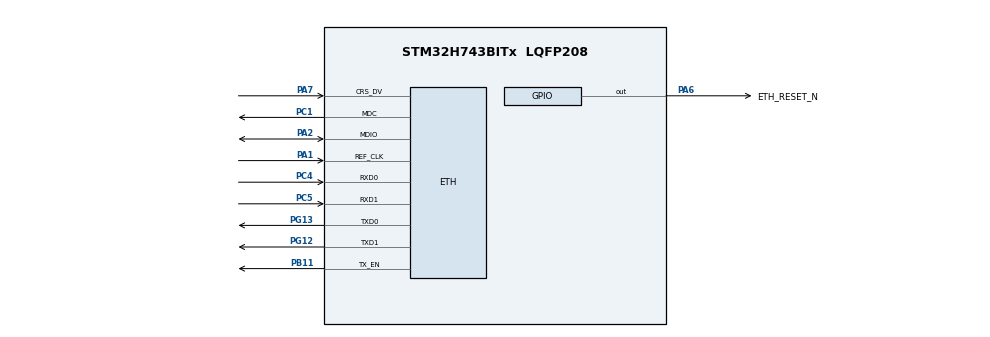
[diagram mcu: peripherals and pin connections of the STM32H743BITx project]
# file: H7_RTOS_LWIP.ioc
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CORTEX_M7.AccessPermission_S-Cortex_Memory_Protection_Unit_Region1_Settings_S=MPU_REGION_FULL_ACCESS
CORTEX_M7.AccessPermission_S-Cortex_Memory_Protection_Unit_Region2_Settings_S=MPU_REGION_FULL_ACCESS
CORTEX_M7.BaseAddress_S-Cortex_Memory_Protection_Unit_Region1_Settings_S=0x30020000
CORTEX_M7.BaseAddress_S-Cortex_Memory_Protection_Unit_Region2_Settings_S=0x30040000
CORTEX_M7.CPU_DCache=Enabled
CORTEX_M7.CPU_ICache=Enabled
CORTEX_M7.DisableExec_S-Cortex_Memory_Protection_Unit_Region1_Settings_S=MPU_INSTRUCTION_ACCESS_DISABLE
CORTEX_M7.DisableExec_S-Cortex_Memory_Protection_Unit_Region2_Settings_S=MPU_INSTRUCTION_ACCESS_DISABLE
CORTEX_M7.Enable_S-Cortex_Memory_Protection_Unit_Region1_Settings_S=MPU_REGION_ENABLE
CORTEX_M7.Enable_S-Cortex_Memory_Protection_Unit_Region2_Settings_S=MPU_REGION_ENABLE
CORTEX_M7.IsBufferable_S-Cortex_Memory_Protection_Unit_Region2_Settings_S=MPU_ACCESS_BUFFERABLE
CORTEX_M7.IsCacheable_S-Cortex_Memory_Protection_Unit_Region2_Settings_S=MPU_ACCESS_NOT_CACHEABLE
CORTEX_M7.IsShareable_S-Cortex_Memory_Protection_Unit_Region2_Settings_S=MPU_ACCESS_SHAREABLE
CORTEX_M7.Size_S-Cortex_Memory_Protection_Unit_Region1_Settings_S=MPU_REGION_SIZE_128KB
CORTEX_M7.Size_S-Cortex_Memory_Protection_Unit_Region2_Settings_S=MPU_REGION_SIZE_512B
CORTEX_M7.TypeExtField_S-Cortex_Memory_Protection_Unit_Region1_Settings_S=MPU_TEX_LEVEL1
CORTEX_M7.TypeExtField_S-Cortex_Memory_Protection_Unit_Region2_Settings_S=MPU_TEX_LEVEL0
CORTEX_M7.default_mode_Activation=1
ETH.MediaInterface=HAL_ETH_RMII_MODE
ETH.RxBufferAddress=0x30040200
ETH.RxDescAddress=0x30040000
ETH.TxDescAddress=0x30040080
FREERTOS.Tasks01=defaultTask,24,256,StartDefaultTask,Default,NULL,Dynamic,NULL,NULL
FREERTOS.configENABLE_FPU=1
LWIP.BSP.number=1
LWIP.LWIP_RAM_HEAP_POINTER=0x30020000
LWIP.MEM_SIZE=131048
LWIP.Version=v2.1.2_Cube
LWIP0.BSP.STBoard=false
LWIP0.BSP.api=BSP_COMPONENT_DRIVER
LWIP0.BSP.component=LAN8742
LWIP0.BSP.instance=LAN8742
LWIP0.BSP.name=Driver_PHY
LWIP0.BSP.semaphore=S_LAN8742
LWIP0.BSP.solution=LAN8742
Mcu.Family=STM32H7
Mcu.Name=STM32H743BITx
Mcu.Package=LQFP208
NVIC.ETH_IRQn=true\:5\:0\:false\:false\:true\:true\:true\:true\:true
NVIC.PriorityGroup=NVIC_PRIORITYGROUP_4
NVIC.TIM6_DAC_IRQn=true\:15\:0\:false\:false\:true\:false\:false\:true\:true
NVIC.TimeBase=TIM6_DAC_IRQn
NVIC.TimeBaseIP=TIM6
PA1.GPIO_Mode=GPIO_MODE_AF_PP
PA1.GPIO_PuPd=GPIO_NOPULL
PA1.GPIO_Speed=GPIO_SPEED_FREQ_VERY_HIGH
PA1.Mode=RMII
PA1.Signal=ETH_REF_CLK
PA13\ (JTMS/SWDIO).Mode=Serial_Wire
PA13\ (JTMS/SWDIO).Signal=DEBUG_JTMS-SWDIO
PA14\ (JTCK/SWCLK).Mode=Serial_Wire
PA14\ (JTCK/SWCLK).Signal=DEBUG_JTCK-SWCLK
PA2.GPIO_Mode=GPIO_MODE_AF_PP
PA2.GPIO_PuPd=GPIO_NOPULL
PA2.GPIO_Speed=GPIO_SPEED_FREQ_VERY_HIGH
PA2.Mode=RMII
PA2.Signal=ETH_MDIO
PA6.GPIO_Label=ETH_RESET_N
PA6.GPIO_Speed=GPIO_SPEED_FREQ_VERY_HIGH
PA6.PinState=GPIO_PIN_SET
PA6.Signal=GPIO_Output
PA7.GPIO_Mode=GPIO_MODE_AF_PP
PA7.GPIO_PuPd=GPIO_NOPULL
PA7.GPIO_Speed=GPIO_SPEED_FREQ_VERY_HIGH
PA7.Mode=RMII
PA7.Signal=ETH_CRS_DV
PB11.GPIO_Mode=GPIO_MODE_AF_PP
PB11.GPIO_PuPd=GPIO_NOPULL
PB11.GPIO_Speed=GPIO_SPEED_FREQ_VERY_HIGH
PB11.Mode=RMII
PB11.Signal=ETH_TX_EN
PC1.GPIO_Mode=GPIO_MODE_AF_PP
PC1.GPIO_PuPd=GPIO_NOPULL
PC1.GPIO_Speed=GPIO_SPEED_FREQ_VERY_HIGH
PC1.Mode=RMII
PC1.Signal=ETH_MDC
PC4.GPIO_Mode=GPIO_MODE_AF_PP
PC4.GPIO_PuPd=GPIO_NOPULL
PC4.GPIO_Speed=GPIO_SPEED_FREQ_VERY_HIGH
PC4.Mode=RMII
PC4.Signal=ETH_RXD0
PC5.GPIO_Mode=GPIO_MODE_AF_PP
PC5.GPIO_PuPd=GPIO_NOPULL
PC5.GPIO_Speed=GPIO_SPEED_FREQ_VERY_HIGH
PC5.Mode=RMII
PC5.Signal=ETH_RXD1
PG12.GPIO_Mode=GPIO_MODE_AF_PP
PG12.GPIO_PuPd=GPIO_NOPULL
PG12.GPIO_Speed=GPIO_SPEED_FREQ_VERY_HIGH
PG12.Mode=RMII
PG12.Signal=ETH_TXD1
PG13.GPIO_Mode=GPIO_MODE_AF_PP
PG13.GPIO_PuPd=GPIO_NOPULL
PG13.GPIO_Speed=GPIO_SPEED_FREQ_VERY_HIGH
PG13.Mode=RMII
PG13.Signal=ETH_TXD0
PH0-OSC_IN\ (PH0).Mode=HSE-External-Oscillator
PH0-OSC_IN\ (PH0).Signal=RCC_OSC_IN
PH1-OSC_OUT\ (PH1).Mode=HSE-External-Oscillator
PH1-OSC_OUT\ (PH1).Signal=RCC_OSC_OUT
ProjectManager.HeapSize=0x800
ProjectManager.StackSize=0x800
ProjectManager.TargetToolchain=MDK-ARM V5.32
RCC.ADCFreq_Value=50390625
RCC.APB1Freq_Value=120000000
RCC.APB2Freq_Value=120000000
RCC.APB3Freq_Value=120000000
RCC.APB4Freq_Value=120000000
RCC.CortexFreq_Value=480000000
RCC.D1PPRE=RCC_APB3_DIV2
RCC.D2PPRE1=RCC_APB1_DIV2
RCC.D2PPRE2=RCC_APB2_DIV2
RCC.D3PPRE=RCC_APB4_DIV2
RCC.DIVM1=5
RCC.DIVN1=192
RCC.HCLKFreq_Value=240000000
RCC.HPRE=RCC_HCLK_DIV2
RCC.PLLSourceVirtual=RCC_PLLSOURCE_HSE
RCC.SYSCLKFreq_VALUE=480000000
RCC.SYSCLKSource=RCC_SYSCLKSOURCE_PLLCLK
RCC.USBFreq_Value=480000000
VP_FREERTOS_VS_CMSIS_V2.Mode=CMSIS_V2
VP_LWIP_VS_Enabled.Mode=Enabled
VP_MEMORYMAP_VS_MEMORYMAP.Mode=CurAppReg
VP_SYS_VS_tim6.Mode=TIM6
board=custom

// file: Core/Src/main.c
/* USER CODE BEGIN Header */
/**
  ******************************************************************************
  * @file           : main.c
  * @brief          : Main program body
  ******************************************************************************
  * @attention
  *
  * Copyright (c) 2024 STMicroelectronics.
  * All rights reserved.
  *
  * This software is licensed under terms that can be found in the LICENSE file
  * in the root directory of this software component.
  * If no LICENSE file comes with this software, it is provided AS-IS.
  *
  ******************************************************************************
  */
/* USER CODE END Header */
#include "main.h"
#include "cmsis_os.h"
#include "lwip.h"
#include "memorymap.h"
#include "gpio.h"

/* USER CODE BEGIN Includes */
#include "dwt.h"
#include "EventRecorder.h"
/* USER CODE END Includes */

void SystemClock_Config(void);
static void MPU_Config(void);
void MX_FREERTOS_Init(void);

int main(void)
{

  /* MPU Configuration--------------------------------------------------------*/
  MPU_Config();

  /* Enable the CPU Cache */

  /* Enable I-Cache---------------------------------------------------------*/
  SCB_EnableICache();

  /* Enable D-Cache---------------------------------------------------------*/
  SCB_EnableDCache();

  /* MCU Configuration--------------------------------------------------------*/

  /* Reset of all peripherals, Initializes the Flash interface and the Systick. */
  HAL_Init();

  /* Configure the system clock */
  SystemClock_Config();

  /* USER CODE BEGIN SysInit */
  __HAL_RCC_D2SRAM2_CLK_ENABLE();//Can be used even if not enabled
  __HAL_RCC_D2SRAM3_CLK_ENABLE();
  /* USER CODE END SysInit */

  /* Initialize all configured peripherals */
  MX_GPIO_Init();
  /* USER CODE BEGIN 2 */
  DWT_Init(480000000);
  EventRecorderInitialize(EventRecordAll, 1);
  /* USER CODE END 2 */

  /* Init scheduler */
  osKernelInitialize();

  /* Call init function for freertos objects (in cmsis_os2.c) */
  MX_FREERTOS_Init();

  /* Start scheduler */
  osKernelStart();

  /* We should never get here as control is now taken by the scheduler */

  /* Infinite loop */
  while (1)
  {

  }
}

void SystemClock_Config(void)
{
  RCC_OscInitTypeDef RCC_OscInitStruct = {0};
  RCC_ClkInitTypeDef RCC_ClkInitStruct = {0};

  /** Supply configuration update enable
  */
  HAL_PWREx_ConfigSupply(PWR_LDO_SUPPLY);

  /** Configure the main internal regulator output voltage
  */
  __HAL_PWR_VOLTAGESCALING_CONFIG(PWR_REGULATOR_VOLTAGE_SCALE1);

  while(!__HAL_PWR_GET_FLAG(PWR_FLAG_VOSRDY)) {}

  __HAL_RCC_SYSCFG_CLK_ENABLE();
  __HAL_PWR_VOLTAGESCALING_CONFIG(PWR_REGULATOR_VOLTAGE_SCALE0);

  while(!__HAL_PWR_GET_FLAG(PWR_FLAG_VOSRDY)) {}

  /** Initializes the RCC Oscillators according to the specified parameters
  * in the RCC_OscInitTypeDef structure.
  */
  RCC_OscInitStruct.OscillatorType = RCC_OSCILLATORTYPE_HSE;
  RCC_OscInitStruct.HSEState = RCC_HSE_ON;
  RCC_OscInitStruct.PLL.PLLState = RCC_PLL_ON;
  RCC_OscInitStruct.PLL.PLLSource = RCC_PLLSOURCE_HSE;
  RCC_OscInitStruct.PLL.PLLM = 5;
  RCC_OscInitStruct.PLL.PLLN = 192;
  RCC_OscInitStruct.PLL.PLLP = 2;
  RCC_OscInitStruct.PLL.PLLQ = 2;
  RCC_OscInitStruct.PLL.PLLR = 2;
  RCC_OscInitStruct.PLL.PLLRGE = RCC_PLL1VCIRANGE_2;
  RCC_OscInitStruct.PLL.PLLVCOSEL = RCC_PLL1VCOWIDE;
  RCC_OscInitStruct.PLL.PLLFRACN = 0;
  if (HAL_RCC_OscConfig(&RCC_OscInitStruct) != HAL_OK)
  {
    Error_Handler();
  }

  /** Initializes the CPU, AHB and APB buses clocks
  */
  RCC_ClkInitStruct.ClockType = RCC_CLOCKTYPE_HCLK|RCC_CLOCKTYPE_SYSCLK
                              |RCC_CLOCKTYPE_PCLK1|RCC_CLOCKTYPE_PCLK2
                              |RCC_CLOCKTYPE_D3PCLK1|RCC_CLOCKTYPE_D1PCLK1;
  RCC_ClkInitStruct.SYSCLKSource = RCC_SYSCLKSOURCE_PLLCLK;
  RCC_ClkInitStruct.SYSCLKDivider = RCC_SYSCLK_DIV1;
  RCC_ClkInitStruct.AHBCLKDivider = RCC_HCLK_DIV2;
  RCC_ClkInitStruct.APB3CLKDivider = RCC_APB3_DIV2;
  RCC_ClkInitStruct.APB1CLKDivider = RCC_APB1_DIV2;
  RCC_ClkInitStruct.APB2CLKDivider = RCC_APB2_DIV2;
  RCC_ClkInitStruct.APB4CLKDivider = RCC_APB4_DIV2;

  if (HAL_RCC_ClockConfig(&RCC_ClkInitStruct, FLASH_LATENCY_4) != HAL_OK)
  {
    Error_Handler();
  }
}

 /* MPU Configuration */

void MPU_Config(void)
{
  MPU_Region_InitTypeDef MPU_InitStruct = {0};

  /* Disables the MPU */
  HAL_MPU_Disable();

  /** Initializes and configures the Region and the memory to be protected
  */
  MPU_InitStruct.Enable = MPU_REGION_ENABLE;
  MPU_InitStruct.Number = MPU_REGION_NUMBER0;
  MPU_InitStruct.BaseAddress = 0x0;
  MPU_InitStruct.Size = MPU_REGION_SIZE_4GB;
  MPU_InitStruct.SubRegionDisable = 0x87;
  MPU_InitStruct.TypeExtField = MPU_TEX_LEVEL0;
  MPU_InitStruct.AccessPermission = MPU_REGION_NO_ACCESS;
  MPU_InitStruct.DisableExec = MPU_INSTRUCTION_ACCESS_DISABLE;
  MPU_InitStruct.IsShareable = MPU_ACCESS_SHAREABLE;
  MPU_InitStruct.IsCacheable = MPU_ACCESS_NOT_CACHEABLE;
  MPU_InitStruct.IsBufferable = MPU_ACCESS_NOT_BUFFERABLE;

  HAL_MPU_ConfigRegion(&MPU_InitStruct);

  /** Initializes and configures the Region and the memory to be protected
  */
  MPU_InitStruct.Number = MPU_REGION_NUMBER1;
  MPU_InitStruct.BaseAddress = 0x30020000;
  MPU_InitStruct.Size = MPU_REGION_SIZE_128KB;
  MPU_InitStruct.SubRegionDisable = 0x0;
  MPU_InitStruct.TypeExtField = MPU_TEX_LEVEL1;
  MPU_InitStruct.AccessPermission = MPU_REGION_FULL_ACCESS;
  MPU_InitStruct.IsShareable = MPU_ACCESS_NOT_SHAREABLE;

  HAL_MPU_ConfigRegion(&MPU_InitStruct);

  /** Initializes and configures the Region and the memory to be protected
  */
  MPU_InitStruct.Number = MPU_REGION_NUMBER2;
  MPU_InitStruct.BaseAddress = 0x30040000;
  MPU_InitStruct.Size = MPU_REGION_SIZE_512B;
  MPU_InitStruct.TypeExtField = MPU_TEX_LEVEL0;
  MPU_InitStruct.IsShareable = MPU_ACCESS_SHAREABLE;
  MPU_InitStruct.IsBufferable = MPU_ACCESS_BUFFERABLE;

  HAL_MPU_ConfigRegion(&MPU_InitStruct);
  /* Enables the MPU */
  HAL_MPU_Enable(MPU_PRIVILEGED_DEFAULT);

}

void HAL_TIM_PeriodElapsedCallback(TIM_HandleTypeDef *htim)
{
  if (htim->Instance == TIM6) {
    HAL_IncTick();
  }
}

void Error_Handler(void)
{
  __disable_irq();
  while (1)
  {
  }
}

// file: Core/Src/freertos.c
/* USER CODE BEGIN Header */
/**
  ******************************************************************************
  * File Name          : freertos.c
  * Description        : Code for freertos applications
  ******************************************************************************
  * @attention
  *
  * Copyright (c) 2024 STMicroelectronics.
  * All rights reserved.
  *
  * This software is licensed under terms that can be found in the LICENSE file
  * in the root directory of this software component.
  * If no LICENSE file comes with this software, it is provided AS-IS.
  *
  ******************************************************************************
  */
/* USER CODE END Header */

#include "FreeRTOS.h"
#include "task.h"
#include "main.h"
#include "cmsis_os.h"

/* USER CODE BEGIN Includes */
#include "netif.h"
#include "tcp_clinet_test.h"
/* USER CODE END Includes */

/* Definitions for defaultTask */
osThreadId_t defaultTaskHandle;
const osThreadAttr_t defaultTask_attributes = {
  .name = "defaultTask",
  .stack_size = 256 * 4,
  .priority = (osPriority_t) osPriorityNormal,
};

void StartDefaultTask(void *argument);

extern void MX_LWIP_Init(void);
void MX_FREERTOS_Init(void); /* (MISRA C 2004 rule 8.1) */

void MX_FREERTOS_Init(void) {

  /* Create the thread(s) */
  /* creation of defaultTask */
  defaultTaskHandle = osThreadNew(StartDefaultTask, NULL, &defaultTask_attributes);

}

void StartDefaultTask(void *argument)
{
  /* init code for LWIP */
  MX_LWIP_Init();
  /* USER CODE BEGIN StartDefaultTask */
  extern struct netif gnetif;
  while (gnetif.ip_addr.addr == 0)
  {
    osDelay(1);
  }

  client_socket_init();

  /* Infinite loop */
  for(;;)
  {
    osDelay(1);
  }
  /* USER CODE END StartDefaultTask */
}
